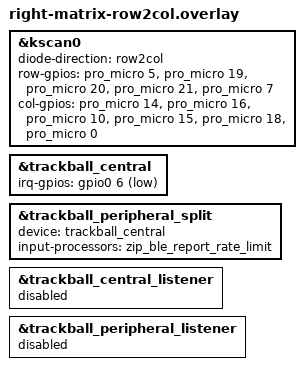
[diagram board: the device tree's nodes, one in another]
/*
 * Candidate only: right-half matrix scan settings for the HeeTuic-modified
 * Crosses46 PCB. Keep the existing shield keymap and col-offset unchanged.
 */

#include <zephyr/dt-bindings/gpio/gpio.h>

&kscan0 {
	 diode-direction = "row2col";

	 row-gpios
	   = <&pro_micro 5 GPIO_ACTIVE_HIGH>
	   , <&pro_micro 19 GPIO_ACTIVE_HIGH>
	   , <&pro_micro 20 GPIO_ACTIVE_HIGH>
	   , <&pro_micro 21 GPIO_ACTIVE_HIGH>
	   , <&pro_micro 7 GPIO_ACTIVE_HIGH>
	   ;

	 col-gpios
	   = <&pro_micro 14 (GPIO_ACTIVE_HIGH | GPIO_PULL_DOWN)>
	   , <&pro_micro 16 (GPIO_ACTIVE_HIGH | GPIO_PULL_DOWN)>
	   , <&pro_micro 10 (GPIO_ACTIVE_HIGH | GPIO_PULL_DOWN)>
	   , <&pro_micro 15 (GPIO_ACTIVE_HIGH | GPIO_PULL_DOWN)>
	   , <&pro_micro 18 (GPIO_ACTIVE_HIGH | GPIO_PULL_DOWN)>
	   , <&pro_micro  0 (GPIO_ACTIVE_HIGH | GPIO_PULL_DOWN)>
	   ;
};

&trackball_central {
    /delete-property/ invert-x;
    /delete-property/ invert-y;
    irq-gpios = <&gpio0 6 (GPIO_ACTIVE_LOW | GPIO_PULL_UP)>;
};

// Right is the peripheral: send the raw right-ball XY to the left central.
&trackball_peripheral_split {
    device = <&trackball_central>;
    input-processors = <&zip_ble_report_rate_limit>;
};

&trackball_central_listener {
    status = "disabled";
};

&trackball_peripheral_listener {
    status = "disabled";
};
